# STM32GBK1CB register map
File version: 1.0
Registers are 32-bit, read-write, reset 0x0 unless marked. A register's access mark holds for its fields unless they carry their own. Offsets are from the block's base; [hi:lo] are bit positions; lines under a group give offsets from that group; {n}, {i} and the like mark numbered series.

## FLASH — FLASH Registers
Base 0x40022000
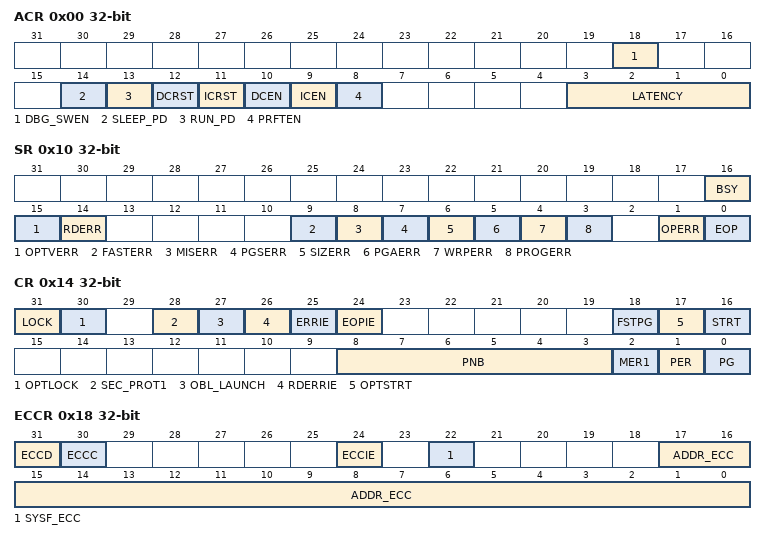
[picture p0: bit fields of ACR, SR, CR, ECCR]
0x00 ACR — FLASH access control register
  [18] DBG_SWEN — Software disable for debugger
  [14] SLEEP_PD — Flash power down mode during sleep
  [13] RUN_PD — Flash power down mode during run
  [12] DCRST
  [11] ICRST
  [10] DCEN
  [9] ICEN
  [8] PRFTEN
  [3:0] LATENCY
    0=FLASH Zero wait state; 1=FLASH One wait state; 2=FLASH Two wait states; 3=FLASH Three wait states; 4=FLASH Four wait states; 5=FLASH five wait state; 6=FLASH six wait state; 7=FLASH seven wait states; 8=FLASH eight wait states; 9=FLASH nine wait states; 10=FLASH ten wait states; 11=FLASH eleven wait states; 12=FLASH twelve wait states; 13=FLASH thirteen wait states; 14=FLASH fourteen wait states; 15=FLASH fifteen wait states
0x04 PDKEYR — FLASH power down key register
0x08 KEYR — FLASH key register
0x0C OPTKEYR — FLASH option key register
0x10 SR — FLASH status register
  [16] BSY, [15] OPTVERR, [14] RDERR, [9] FASTERR, [8] MISERR, [7] PGSERR, [6] SIZERR, [5] PGAERR, [4] WRPERR, [3] PROGERR, [1] OPERR, [0] EOP
0x14 CR — FLASH control register
  [31] LOCK, [30] OPTLOCK, [28] SEC_PROT1, [27] OBL_LAUNCH, [26] RDERRIE, [25] ERRIE, [24] EOPIE, [18] FSTPG, [17] OPTSTRT, [16] STRT, [8:3] PNB, [2] MER1, [1] PER, [0] PG
0x18 ECCR — FLASH ECC register
  [31] ECCD, [30] ECCC, [24] ECCIE, [22] SYSF_ECC, [17:0] ADDR_ECC
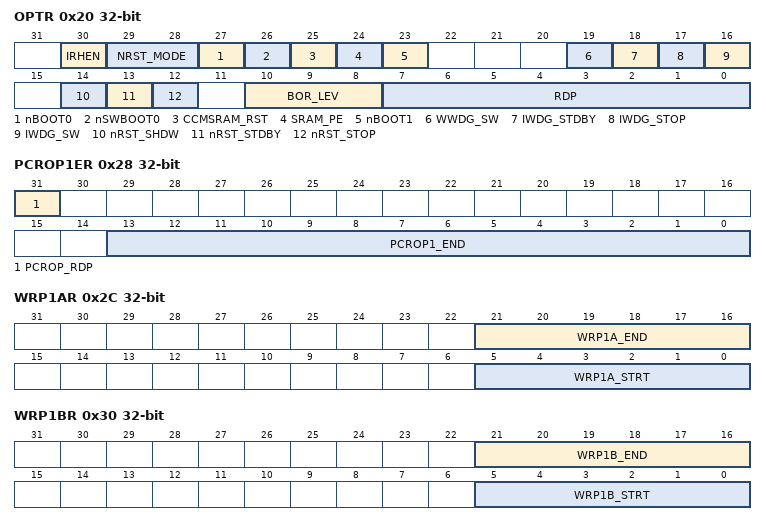
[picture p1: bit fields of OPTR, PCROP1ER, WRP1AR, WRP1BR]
0x20 OPTR — FLASH option register
  [30] IRHEN, [29:28] NRST_MODE, [27] nBOOT0, [26] nSWBOOT0, [25] CCMSRAM_RST, [24] SRAM_PE, [23] nBOOT1, [19] WWDG_SW, [18] IWDG_STDBY, [17] IWDG_STOP, [16] IWDG_SW, [14] nRST_SHDW, [13] nRST_STDBY, [12] nRST_STOP, [10:8] BOR_LEV, [7:0] RDP
0x24 PCROP1SR — FLASH bank1 PCROP start address register
  [13:0] PCROP1_STRT
0x28 PCROP1ER — FLASH bank1 PCROP end address register
  [31] PCROP_RDP, [13:0] PCROP1_END
0x2C WRP1AR — FLASH bank1 WRP area A address register
  [21:16] WRP1A_END, [5:0] WRP1A_STRT
0x30 WRP1BR — FLASH bank1 WRP area B address register
  [21:16] WRP1B_END, [5:0] WRP1B_STRT
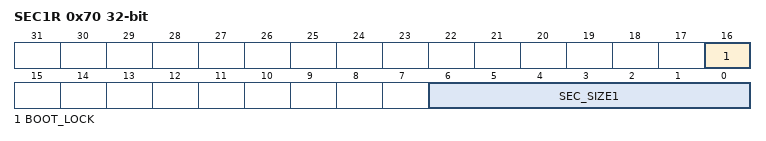
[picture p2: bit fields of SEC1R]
0x70 SEC1R — FLASH Securable memory register bank1
  [16] BOOT_LOCK, [6:0] SEC_SIZE1

## CRC — CRC calculation unit
Base 0x40023000
0x00 DR — CRC Data register
  [31:0] DR — Data register bits
0x04 IDR — CRC Independent data register
  [31:0] IDR — General-purpose 32-bit data register bits
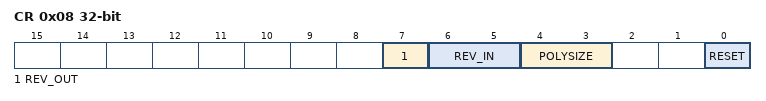
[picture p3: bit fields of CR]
0x08 CR — CRC Control register
  [7] REV_OUT — REV_OUT Reverse Output Data bits
    0=NONE (Output Data bit order not affected); 1=BIT (Output Data bit reversal done by bit)
  [6:5] REV_IN — REV_IN Reverse Input Data bits
    0=NONE (Input Data bit order not affected); 1=BYTE (Input Data bit reversal done by byte); 2=HALFWORD (Input Data bit reversal done by half-word); 3=WORD (Input Data bit reversal done by word)
  [4:3] POLYSIZE — Polynomial size bits
    0=POLYLENGTH_32B (32 bits Polynomial size); 1=POLYLENGTH_16B (16 bits Polynomial size); 2=POLYLENGTH_8B (8 bits Polynomial size); 3=POLYLENGTH_7B (7 bits Polynomial size)
  [0] RESET — RESET the CRC computation unit bit
0x10 INIT — Initial CRC value register
  [31:0] INIT — Initial CRC value bits
0x14 POL — CRC polynomial register
  [31:0] POL — Coefficients of the polynomial

## GPIOA — General Purpose I/O
Base 0x48000000
Same registers: GPIOB 0x48000400, GPIOC 0x48000800, GPIOD 0x48000C00, GPIOE 0x48001000, GPIOF 0x48001400, GPIOG 0x48001800
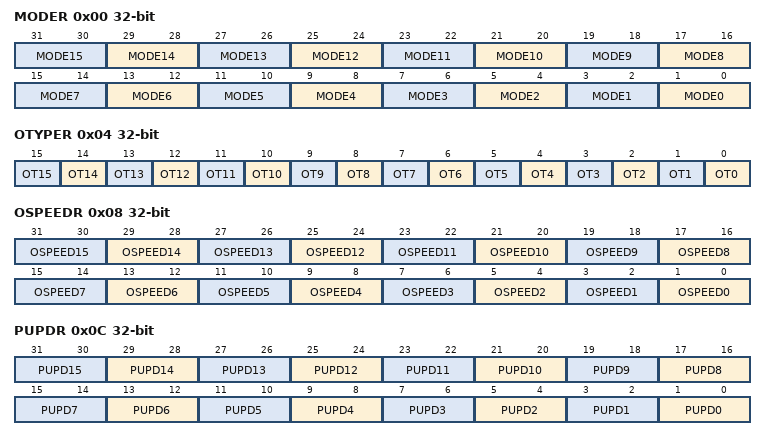
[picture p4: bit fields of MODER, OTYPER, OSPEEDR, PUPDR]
0x00 MODER — GPIO port mode register
  [2n+1:2n] MODE{n} (n=0..15)
0x04 OTYPER — GPIO port output type register
  [n] OT{n} (n=0..15)
0x08 OSPEEDR — GPIO port output speed register
  [2n+1:2n] OSPEED{n} (n=0..15)
0x0C PUPDR — GPIO port pull-up/pull-down register
  [2n+1:2n] PUPD{n} (n=0..15)
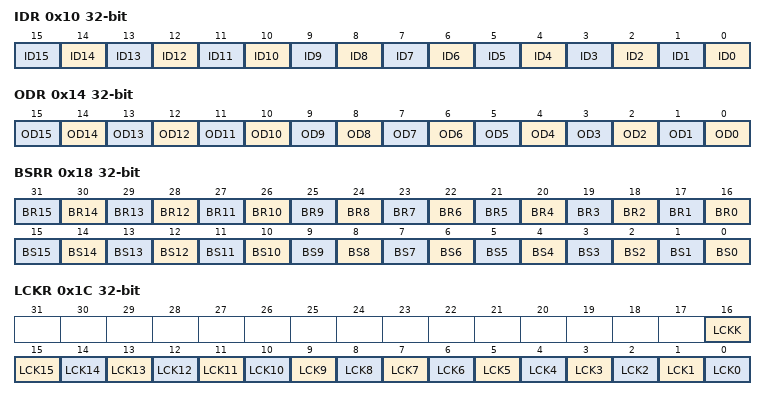
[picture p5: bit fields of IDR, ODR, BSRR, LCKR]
0x10 IDR — GPIO port input data register
  [n] ID{n} (n=0..15)
0x14 ODR — GPIO port output data register
  [n] OD{n} (n=0..15)
0x18 BSRR — GPIO port bit set/reset register
  [n+16] BR{n} (n=0..15), [n] BS{n} (n=0..15)
0x1C LCKR — GPIO port configuration lock register
  [16] LCKK, [n] LCK{n} (n=0..15)
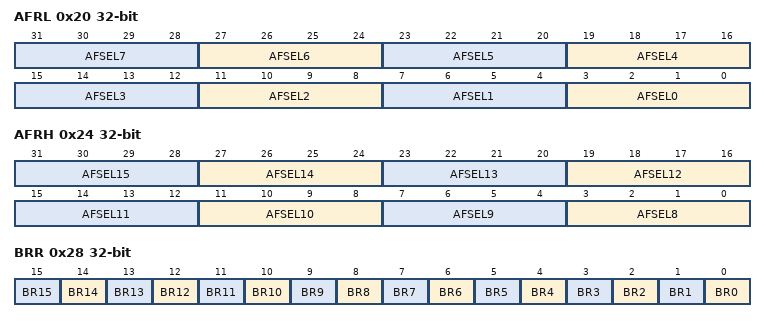
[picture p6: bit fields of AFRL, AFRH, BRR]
0x20 AFRL — GPIO alternate function registers
  [4n+3:4n] AFSEL{n} (n=0..7)
0x24 AFRH — GPIO alternate function registers
  [4n-29:4n-32] AFSEL{n} (n=8..15)
0x28 BRR — GPIO Bit Reset register
  [n] BR{n} (n=0..15)

## ADC12_COMMON
Base 0x50000300
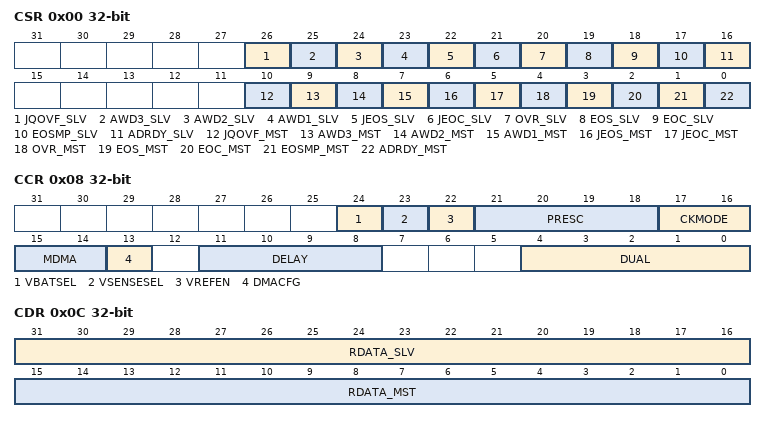
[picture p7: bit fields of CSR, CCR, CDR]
0x00 CSR — ADC common status register
  [26] JQOVF_SLV — ADC multimode slave group injected contexts queue overflow flag
  [25] AWD3_SLV — ADC multimode slave analog watchdog 3 flag
  [24] AWD2_SLV — ADC multimode slave analog watchdog 2 flag
  [23] AWD1_SLV — ADC multimode slave analog watchdog 1 flag
  [22] JEOS_SLV — ADC multimode slave group injected end of sequence conversions flag
  [21] JEOC_SLV — ADC multimode slave group injected end of unitary conversion flag
  [20] OVR_SLV — ADC multimode slave group regular overrun flag
  [19] EOS_SLV — ADC multimode slave group regular end of sequence conversions flag
  [18] EOC_SLV — ADC multimode slave group regular end of unitary conversion flag
  [17] EOSMP_SLV — ADC multimode slave group regular end of sampling flag
  [16] ADRDY_SLV — ADC multimode slave ready flag
  [10] JQOVF_MST — ADC multimode master group injected contexts queue overflow flag
  [9] AWD3_MST — ADC multimode master analog watchdog 3 flag
  [8] AWD2_MST — ADC multimode master analog watchdog 2 flag
  [7] AWD1_MST — ADC multimode master analog watchdog 1 flag
  [6] JEOS_MST — ADC multimode master group injected end of sequence conversions flag
  [5] JEOC_MST — ADC multimode master group injected end of unitary conversion flag
  [4] OVR_MST — ADC multimode master group regular overrun flag
  [3] EOS_MST — ADC multimode master group regular end of sequence conversions flag
  [2] EOC_MST — ADC multimode master group regular end of unitary conversion flag
  [1] EOSMP_MST — ADC multimode master group regular end of sampling flag
  [0] ADRDY_MST — ADC multimode master ready flag
0x08 CCR — ADC common configuration register
  [24] VBATSEL — ADC internal path to battery voltage enable
  [23] VSENSESEL — ADC internal path to temperature sensor enable
  [22] VREFEN — ADC internal path to VrefInt enable
  [21:18] PRESC — ADC common clock prescaler, only for clock source asynchronous
  [17:16] CKMODE — ADC common clock source and prescaler (prescaler only for clock source synchronous)
  [15:14] MDMA — ADC multimode DMA transfer enable
  [13] DMACFG — ADC multimode DMA transfer configuration
  [11:8] DELAY — ADC multimode delay between 2 sampling phases
    0=DELAY_1CYCLE; {v}=DELAY_{v+1}CYCLES (v=1..11)
  [4:0] DUAL — ADC multimode mode selection
    0=INDEPENDENT; 6=DUAL_REG_SIMULT; 7=DUAL_REG_INTERL; 5=DUAL_INJ_SIMULT; 9=DUAL_INJ_ALTERN; 1=DUAL_REG_SIM_INJ_SIM; 2=DUAL_REG_SIM_INJ_ALT; 3=DUAL_REG_INT_INJ_SIM
0x0C CDR — ADC common group regular data register
  [31:16] RDATA_SLV — ADC multimode slave group regular conversion data
  [15:0] RDATA_MST — ADC multimode master group regular conversion data

## RNG
Base 0x50060800
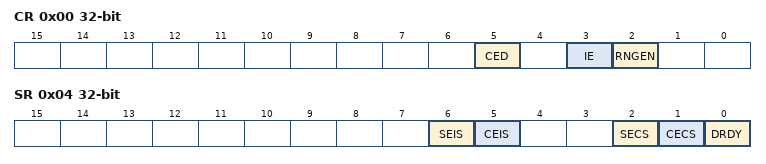
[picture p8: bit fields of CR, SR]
0x00 CR — RNG control register
  [5] CED, [3] IE, [2] RNGEN
0x04 SR — RNG status register
  [6] SEIS, [5] CEIS, [2] SECS, [1] CECS, [0] DRDY
0x08 DR — RNG data register

## DBGMCU — Debug MCU
Base 0xE0042000
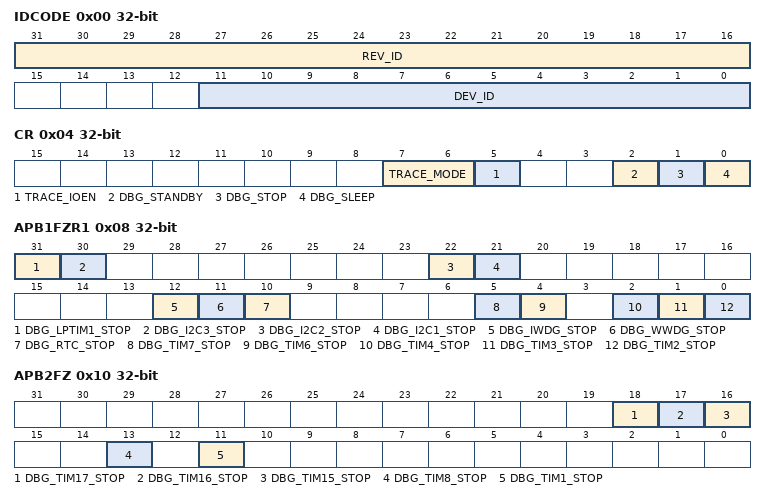
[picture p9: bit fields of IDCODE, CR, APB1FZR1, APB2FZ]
0x00 IDCODE — MCU device ID code
  [31:16] REV_ID, [11:0] DEV_ID
0x04 CR — Debug MCU configuration register
  [7:6] TRACE_MODE, [5] TRACE_IOEN, [2] DBG_STANDBY, [1] DBG_STOP, [0] DBG_SLEEP
0x08 APB1FZR1 — Debug MCU APB1 freeze register 1
  [31] DBG_LPTIM1_STOP, [30] DBG_I2C3_STOP, [22] DBG_I2C2_STOP, [21] DBG_I2C1_STOP, [12] DBG_IWDG_STOP, [11] DBG_WWDG_STOP, [10] DBG_RTC_STOP, [5] DBG_TIM7_STOP, [4] DBG_TIM6_STOP, [2] DBG_TIM4_STOP, [1] DBG_TIM3_STOP, [0] DBG_TIM2_STOP
0x0C APB1FZR2 — Debug MCU APB1 freeze register 2
0x10 APB2FZ — Debug MCU APB2 freeze register
  [18] DBG_TIM17_STOP, [17] DBG_TIM16_STOP, [16] DBG_TIM15_STOP, [13] DBG_TIM8_STOP, [11] DBG_TIM1_STOP
